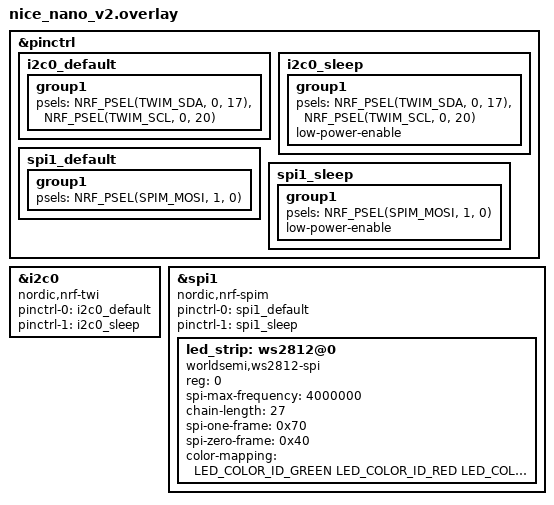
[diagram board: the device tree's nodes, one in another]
#include <dt-bindings/led/led.h>

&pinctrl {
    i2c0_default: i2c0_default {
        group1 {
            psels = <NRF_PSEL(TWIM_SDA, 0, 17)>,
                    <NRF_PSEL(TWIM_SCL, 0, 20)>;
        };
    };

    i2c0_sleep: i2c0_sleep {
        group1 {
            psels = <NRF_PSEL(TWIM_SDA, 0, 17)>,
                    <NRF_PSEL(TWIM_SCL, 0, 20)>;
            low-power-enable;
        };
    };

    spi1_default: spi1_default {
        group1 {
            psels = <NRF_PSEL(SPIM_MOSI, 1, 0)>;
        };
    };

    spi1_sleep: spi1_sleep {
        group1 {
            psels = <NRF_PSEL(SPIM_MOSI, 1, 0)>;
            low-power-enable;
        };
    };
};

&i2c0 {
    compatible = "nordic,nrf-twi";
    status = "okay";
    pinctrl-0 = <&i2c0_default>;
    pinctrl-1 = <&i2c0_sleep>;
    pinctrl-names = "default", "sleep";
};

&spi1 {
    compatible = "nordic,nrf-spim";
    status = "okay";
    pinctrl-0 = <&spi1_default>;
    pinctrl-1 = <&spi1_sleep>;
    pinctrl-names = "default", "sleep";

    led_strip: ws2812@0 {
        compatible = "worldsemi,ws2812-spi";
        reg = <0>;
        spi-max-frequency = <4000000>;
        chain-length = <27>;
        spi-one-frame = <0x70>;
        spi-zero-frame = <0x40>;
        color-mapping = <LED_COLOR_ID_GREEN LED_COLOR_ID_RED LED_COLOR_ID_BLUE>;
    };
};
